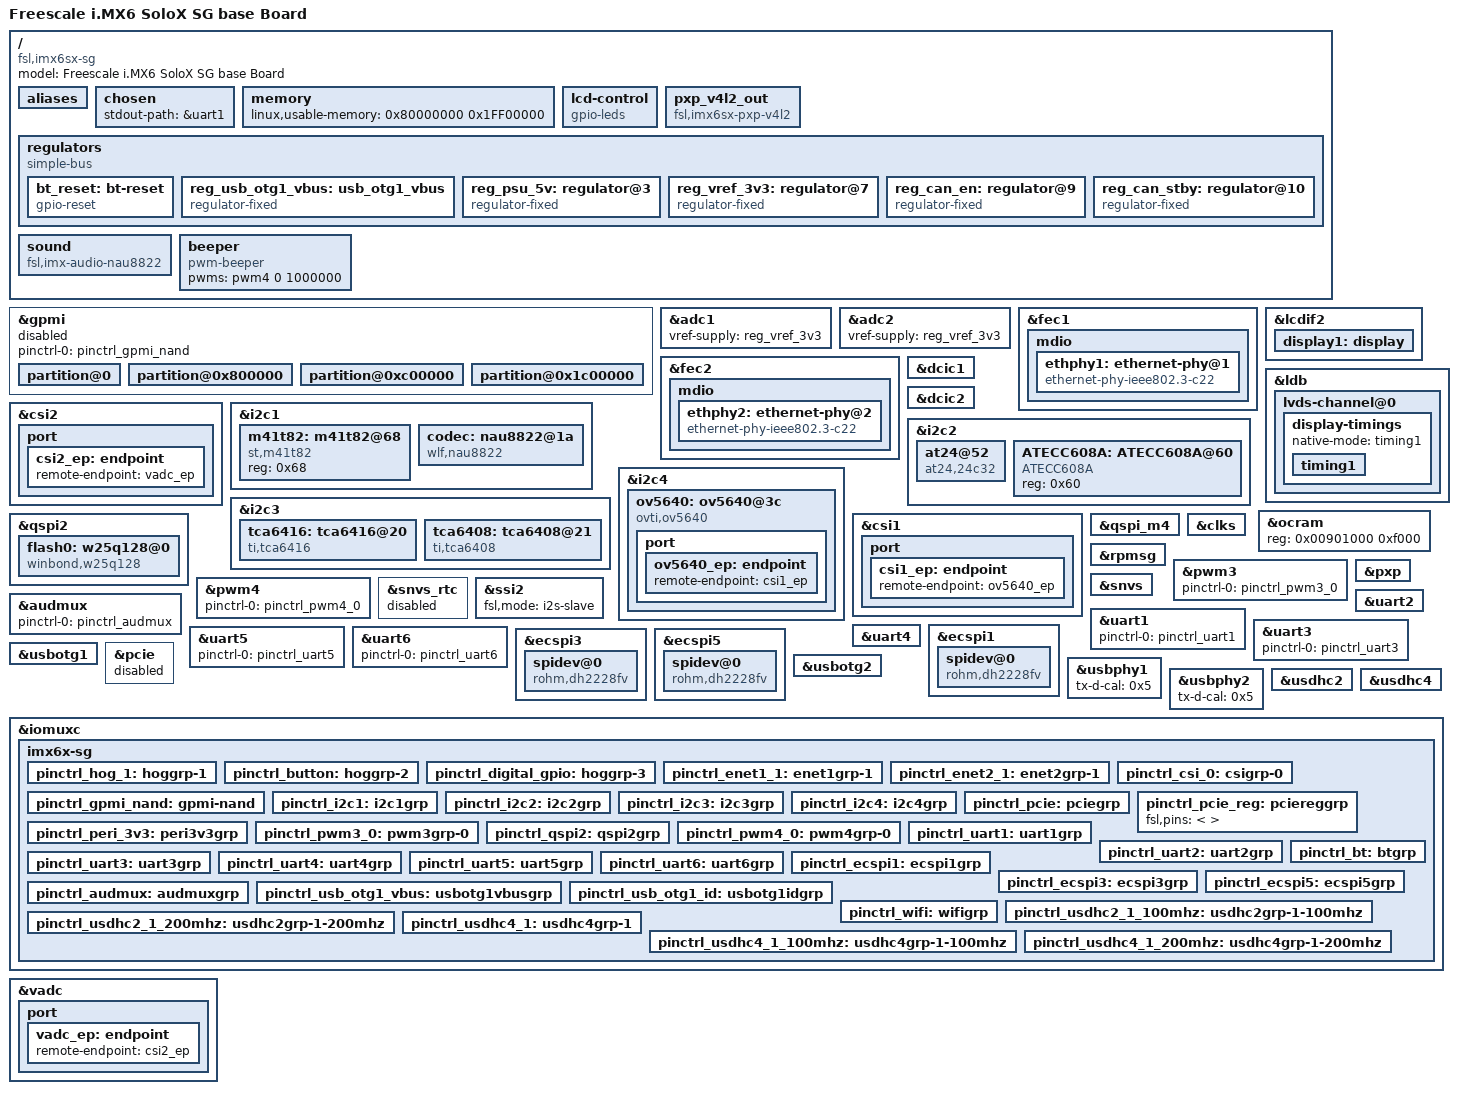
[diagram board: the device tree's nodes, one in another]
/*
 * Copyright (C) 2014 Freescale Semiconductor, Inc.
 *
 * This program is free software; you can redistribute it and/or modify
 * it under the terms of the GNU General Public License version 2 as
 * published by the Free Software Foundation.
 */

/dts-v1/;

#include <dt-bindings/gpio/gpio.h>
#include <dt-bindings/input/input.h>
#include "imx6sx.dtsi"

/ {
	model = "Freescale i.MX6 SoloX SG base Board";
	compatible = "fsl,imx6sx-sg", "fsl,imx6sx";
	
	aliases {
        
    };
	
	chosen {
		stdout-path = &uart1;
		//stdout-path = &mxcfb1;
	};

	memory {
		linux,usable-memory = <0x80000000 0x1FF00000>;
	};
	
	lcd-control {
		compatible = "gpio-leds";
	};

	pxp_v4l2_out {
		compatible = "fsl,imx6sx-pxp-v4l2", "fsl,imx6sl-pxp-v4l2";
		status = "okay";
	};

	regulators {
		compatible = "simple-bus";
		#address-cells = <1>;
		#size-cells = <0>;

        bt_reset: bt-reset {
			compatible = "gpio-reset";
			reset-gpios = <&gpio1 2 GPIO_ACTIVE_LOW>;
			reset-delay-us = <1000>;
			#reset-cells = <0>;
		};

		reg_usb_otg1_vbus: usb_otg1_vbus {
			compatible = "regulator-fixed";
			reg = <1>;
			pinctrl-names = "default";
			pinctrl-0 = <&pinctrl_usb_otg1_vbus>;
			regulator-name = "usb_otg1_vbus";
			regulator-min-microvolt = <5000000>;
			regulator-max-microvolt = <5000000>;
			gpio = <&gpio4 18 GPIO_ACTIVE_HIGH>;
			enable-active-high;
		};
		
		reg_psu_5v: regulator@3 {
			compatible = "regulator-fixed";
			reg = <3>;
			regulator-name = "PSU-5V0";
			regulator-min-microvolt = <5000000>;
			regulator-max-microvolt = <5000000>;
		};

		reg_vref_3v3: regulator@7 {
			compatible = "regulator-fixed";
			reg = <7>;
			regulator-name = "vref-3v3";
			regulator-min-microvolt = <3300000>;
			regulator-max-microvolt = <3300000>;
		};

		reg_can_en: regulator@9 {
			compatible = "regulator-fixed";
			reg = <9>;
			regulator-name = "can-en";
			regulator-min-microvolt = <3300000>;
			regulator-max-microvolt = <3300000>;
		};

		reg_can_stby: regulator@10 {
			compatible = "regulator-fixed";
			reg = <10>;
			regulator-name = "can-stby";
			regulator-min-microvolt = <3300000>;
			regulator-max-microvolt = <3300000>;
		};
	};

	sound {
		compatible = "fsl,imx-audio-nau8822";
		model = "nau8822-audio";
		ssi-controller = <&ssi2>;
		audio-codec = <&codec>;
		audio-routing =
			"Mic Bias", "AMIC";
		mux-int-port = <2>;
		mux-ext-port = <3>;
	};
	beeper {
        compatible = "pwm-beeper";
        pwms = <&pwm4 0 1000000>;
        status = "okay";
    };
};

&gpmi {
	pinctrl-names = "default";
	pinctrl-0 = <&pinctrl_gpmi_nand>;
	status = "disabled"; 
	partition@0 {
	label = "uboot";
	reg = <0 0x800000>;
	};
	partition@0x800000 {
		label = "env";
		reg = <0x800000 0x400000>;
	};
	partition@0xc00000 {
	label = "system";
	reg = <0xc00000 0x2000000>;
	};
	partition@0x1c00000 {
	label = "rootfs";
	reg = <0x2c00000 0x3d400000>;
	};
};

&adc1 {
	vref-supply = <&reg_vref_3v3>;
	status = "okay";
};

&adc2 {
	vref-supply = <&reg_vref_3v3>;
	status = "okay";
};

&fec1 {
	pinctrl-names = "default";
	pinctrl-0 = <&pinctrl_enet1_1>;
	phy-mode = "rgmii";
	phy-handle = <&ethphy1>;
	phy-reset-gpios = <&gpio2 4 1>; 
	phy-reset-duration =<20>;
   	local-mac-address = [00 04 9F 01 1B 58];
	status = "okay";
	
	mdio {
		#address-cells = <1>;
		#size-cells = <0>;

		ethphy1: ethernet-phy@1 {
			compatible = "ethernet-phy-ieee802.3-c22";
			reg = <1>;
			micrel,led-mode = <0>;
		};
			
	};
        
	
};

&fec2 {
	pinctrl-names = "default";
	pinctrl-0 = <&pinctrl_enet2_1>;
	phy-mode = "rgmii";
	phy-handle = <&ethphy2>;  	
	phy-reset-gpios = <&gpio2 2 1>; 
	phy-reset-duration =<20>;
   	local-mac-address = [00 04 9F 01 1B 68];
	status = "okay";
       
	mdio {
		#address-cells = <1>;
		#size-cells = <0>;

		
		ethphy2: ethernet-phy@2 {
			compatible = "ethernet-phy-ieee802.3-c22";
			reg = <2>;
			micrel,led-mode = <0>;
		};

		
	};
	
};

&lcdif2 {
	//pinctrl-names = "default";
	//pinctrl-0 = <&pinctrl_lcd>;
	display = <&display1>;
	disp-dev = "ldb";
	status = "okay";
	display1: display {
		bits-per-pixel = <32>;
		bus-width = <24>;
	};
};
&ldb {
    status = "okay";
	lvds-channel@0 {
		fsl,data-mapping = "spwg";//"jeida";
		fsl,data-width = <24>;
		crtc = "lcdif2";
		status = "okay";
		display-timings {
			native-mode = <&timing1>;
			timing1: timing1 {
				clock-frequency = <51200000>;
				hactive = <1024>;
				vactive = <600>;
				hback-porch = <100>;
				hfront-porch = <100>;
				hsync-len = <120>;
				vback-porch = <10>;
				vfront-porch = <10>;
				vsync-len = <15>;
				//de-active = <1>;
			};
		};
	};
};

&csi2 {
	status = "okay";
	port {
		csi2_ep: endpoint {
			remote-endpoint = <&vadc_ep>;
		};
	};
};

&dcic1 {
	dcic_id = <0>;
	dcic_mux = "dcic-lcdif1";
	status = "okay";
};

&dcic2 {
	dcic_id = <1>;
	dcic_mux = "dcic-lvds";
	status = "okay";
};

&i2c1 {
	clock-frequency = <100000>;
        pinctrl-names = "default";
        pinctrl-0 = <&pinctrl_i2c1>;
        status = "okay";
	m41t82: m41t82@68 {
		compatible = "st,m41t82";
		reg = <0x68>;
            	status = "okay"; 
	};

	codec: nau8822@1a {
		compatible = "wlf,nau8822";
		reg = <0x1a>;
		clocks = <&clks IMX6SX_CLK_AUDIO>;
	};
};

&i2c2 {
	clock-frequency = <100000>;
        pinctrl-names = "default";
        pinctrl-0 = <&pinctrl_i2c2>;
	status = "okay";

	at24@52 {
		compatible = "at24,24c32";
		pagesize = <32>;
		reg = <0x52>;
	};
	
	ATECC608A: ATECC608A@60 {
		compatible = "ATECC608A";
		reg = <0x60>;
	};	
};

&i2c3 {
	clock-frequency = <100000>;
	pinctrl-names = "default";
	pinctrl-0 = <&pinctrl_i2c3>;
	status = "okay";
	
	tca6416: tca6416@20 {
		compatible = "ti,tca6416";
		reg = <0x20>;
		#gpio-cells = <2>;
		gpio-controller;
	};
	
	tca6408: tca6408@21 {
		compatible = "ti,tca6408";
		reg = <0x21>;
		#gpio-cells = <2>;
		gpio-controller;
	};
};

&i2c4 {
    status = "okay";
    clock-frequency = <100000>;
    pinctrl-names = "default";
    pinctrl-0 = <&pinctrl_i2c4>;

	ov5640: ov5640@3c {
		compatible = "ovti,ov5640";
		reg = <0x3c>;
		pinctrl-names = "default";
		pinctrl-0 = <&pinctrl_csi_0>;
		clocks = <&clks IMX6SX_CLK_CSI>;
		clock-names = "csi_mclk";
		cam18v-en-gpios = <&tca6416 14 0>;
		cam28v-en-gpios = <&tca6416 15 0>;
		pwn-gpios = <&gpio3 18 1>;
		rst-gpios = <&gpio3 17 0>;
		csi_id = <0>;
		mclk = <24000000>;
		mclk_source = <0>;
		port {
			ov5640_ep: endpoint {
				remote-endpoint = <&csi1_ep>;
			};
		};
	};
};

&csi1 {
    status = "okay";

    port {
        csi1_ep: endpoint {
            remote-endpoint = <&ov5640_ep>;
        };
    };
};

&ocram {
	reg = <0x00901000 0xf000>;
};

&qspi2 {
	pinctrl-names = "default";
	pinctrl-0 = <&pinctrl_qspi2>;
	status = "okay";
	ddrsmp=<0>;	//or 2

	flash0: w25q128@0 {
		#address-cells = <1>;
		#size-cells = <1>;
		compatible = "winbond,w25q128";
		spi-max-frequency = <15625000>;
		reg = <0>;
	};
};

&qspi_m4 {
	status = "okay";
};

&rpmsg{
	status = "okay";
};

&clks {
	fsl,shared-clks-number = <0x23>;//<0x1A>;
	fsl,shared-clks-index = <IMX6SX_CLK_PLL2_BUS IMX6SX_CLK_PLL2_PFD0
			IMX6SX_CLK_PLL2_PFD2 IMX6SX_CLK_PLL3_USB_OTG
			IMX6SX_CLK_PLL3_PFD1 IMX6SX_CLK_PLL3_PFD2
			IMX6SX_CLK_PLL3_PFD3 IMX6SX_CLK_PLL4_AUDIO
			IMX6SX_CLK_PLL5_VIDEO
			IMX6SX_CLK_OCRAM IMX6SX_CLK_CAN1_SERIAL
			IMX6SX_CLK_CAN1_IPG IMX6SX_CLK_CAN2_SERIAL
			IMX6SX_CLK_CAN2_IPG IMX6SX_CLK_CANFD
			IMX6SX_CLK_ECSPI1 IMX6SX_CLK_ECSPI2
			IMX6SX_CLK_ECSPI3 IMX6SX_CLK_ECSPI4
			IMX6SX_CLK_ECSPI5 IMX6SX_CLK_QSPI1
			IMX6SX_CLK_QSPI2 IMX6SX_CLK_SSI1
			IMX6SX_CLK_SSI2 IMX6SX_CLK_SSI3
			IMX6SX_CLK_UART_SERIAL IMX6SX_CLK_UART_IPG
			IMX6SX_CLK_PERIPH_CLK2_SEL IMX6SX_CLK_DUMMY
			IMX6SX_CLK_I2C1 IMX6SX_CLK_I2C2
			IMX6SX_CLK_I2C3 IMX6SX_CLK_I2C4
			IMX6SX_CLK_EPIT1 IMX6SX_CLK_EPIT2>;
	fsl,shared-mem-addr = <0x91F000>;
	fsl,shared-mem-size = <0x1000>;
};

&pwm3 {
	pinctrl-names = "default";
	pinctrl-0 = <&pinctrl_pwm3_0>;
	status = "okay";
};

&pwm4 {
	pinctrl-names = "default";
	pinctrl-0 = <&pinctrl_pwm4_0>;
	status = "okay";
};


&pxp {
    status = "okay";
};

&snvs{
	status = "okay";
};

&snvs_rtc {
    status = "disabled";
};

&ssi2 {
	fsl,mode = "i2s-slave";
	status = "okay";
};

&audmux {  
    pinctrl-names = "default";  
    pinctrl-0 = <&pinctrl_audmux>;  
    status = "okay";  
};

//debug serial
&uart1 {
	pinctrl-names = "default";
	pinctrl-0 = <&pinctrl_uart1>;
	status = "okay";
};

//BM28: BT
&uart2 {
	pinctrl-names = "default";
	    pinctrl-0 = <&pinctrl_uart2
                        &pinctrl_bt>;
    fsl,uart-has-rtscts;
    resets = <&bt_reset>;
	status = "okay";
};

//Port P3: LTE EXPANSION
&uart3 {
	pinctrl-names = "default";
	pinctrl-0 = <&pinctrl_uart3>;
	status = "okay";
};

//Common port2 and module 485
&uart4 {
    pinctrl-names = "default";
    pinctrl-0 = <&pinctrl_uart4>;
	fsl,uart-has-rtscts;
    status = "okay";
};

//Common port1 and module 485
&uart5 {
	pinctrl-names = "default";
	pinctrl-0 = <&pinctrl_uart5>;
	status = "okay";
};

//rs232/ttl232
&uart6 {
	pinctrl-names = "default";
	pinctrl-0 = <&pinctrl_uart6>;
	//fsl,uart-has-rtscts;
	status = "okay";
};

//PORT P1: Common module
&ecspi1 {
	fsl,spi-num-chipselects = <1>;
	cs-gpios = <&gpio4 22 GPIO_ACTIVE_LOW>;
	pinctrl-names = "default";
	pinctrl-0 = <&pinctrl_ecspi1>;
	status = "okay";
	spidev@0 {
		compatible = "rohm,dh2228fv";
		spi-max-frequency = <20000000>;
		reg = <0>;
		dmas = <&sdma 3 7 1>, <&sdma 4 7 2>;
		dma-names = "rx", "tx";
	};
};

//Port P2: Common module
&ecspi3 {
    fsl,spi-num-chipselects = <1>;
    cs-gpios = <&gpio4 30 GPIO_ACTIVE_LOW>;
    
    pinctrl-names = "default";
    pinctrl-0 = <&pinctrl_ecspi3>;
    status = "okay";
    spidev@0 {
            compatible = "rohm,dh2228fv";
            spi-max-frequency = <20000000>;
            reg = <0>;
            dmas = <&sdma 7 7 1>, <&sdma 8 7 2>;
            dma-names = "rx", "tx";
        };
};

//Port P3: LTE EXPANSION
&ecspi5 {
	fsl,spi-num-chipselects = <1>;
	cs-gpios = <&gpio4 28 GPIO_ACTIVE_LOW>;
	pinctrl-names = "default";
	pinctrl-0 = <&pinctrl_ecspi5>;
	status = "okay";
	spidev@0 {
		compatible = "rohm,dh2228fv";
		spi-max-frequency = <20000000>;
		reg = <0>;
		dmas = <&sdma 11 7 1>, <&sdma 12 7 2>;
		dma-names = "rx", "tx";
	};
};

&usbotg1 {
	vbus-supply = <&reg_usb_otg1_vbus>;
	pinctrl-names = "default";
	pinctrl-0 = <&pinctrl_usb_otg1_id>;
	//disable-over-current;
	srp-disable;
	hnp-disable;
	adp-disable;
    dr_mode = "otg";
	status = "okay";
};

//Port P3: LTE EXPANSION
&usbotg2 {
        pinctrl-names = "default";
        srp-disable;
        hnp-disable;
        adp-disable;
        dr_mode = "host";
        status = "okay";
};

&usbphy1 {
        tx-d-cal = <0x5>;
};

&usbphy2 {
        tx-d-cal = <0x5>;
};

//BM28: Wifi
&usdhc2 {
	pinctrl-names = "default", "state_100mhz", "state_200mhz";
	pinctrl-0 = <&pinctrl_wifi>;
        pinctrl-1 = <&pinctrl_usdhc2_1_100mhz>;
        pinctrl-2 = <&pinctrl_usdhc2_1_200mhz>;
	non-removable;
	wifi-host;
	keep-power-in-suspend;
	enable-sdio-wakeup;
	status = "okay";
};

&usdhc4 {
	pinctrl-names = "default";
	pinctrl-0 = <&pinctrl_usdhc4_1>;
	bus-width = <8>;
	non-removable;
	no-1-8-v;
	keep-power-in-suspend;
	enable-sdio-wakeup;
	status = "okay";
};

&pcie {
	pinctrl-names = "default";
	pinctrl-0 = <&pinctrl_pcie>;
	reset-gpio = <&gpio3 4 0>;
	disable-gpio = <&gpio4 4 0>;
	status = "disabled";
};

&iomuxc {
	pinctrl-names = "default";
	pinctrl-0 = <
        &pinctrl_hog_1
        &pinctrl_button
        &pinctrl_digital_gpio
    >;
	imx6x-sg {
		pinctrl_hog_1: hoggrp-1 {
			fsl,pins = <
				MX6SX_PAD_USB_H_DATA__GPIO7_IO_10	0x83030
			>;
		};
		
        pinctrl_button: hoggrp-2 {
            fsl,pins = <
                /* button pull up */
                MX6SX_PAD_GPIO1_IO11__GPIO1_IO_11        0xF000
                MX6SX_PAD_NAND_RE_B__GPIO4_IO_12         0xF000
            >;
        };

        pinctrl_digital_gpio: hoggrp-3 {
            fsl,pins = <
				MX6SX_PAD_LCD1_DATA00__GPIO3_IO_1        0x110b0
				MX6SX_PAD_LCD1_DATA01__GPIO3_IO_2        0x110b0
                MX6SX_PAD_LCD1_DATA02__GPIO3_IO_3        0x110b0
                MX6SX_PAD_LCD1_DATA23__GPIO3_IO_24       0x110b0
           >;
        };

		pinctrl_enet1_1: enet1grp-1 {
			fsl,pins = <
				MX6SX_PAD_ENET2_COL__ENET1_MDC        	0xa0b1 
				MX6SX_PAD_ENET2_CRS__ENET1_MDIO        	0xa0b1 
				MX6SX_PAD_RGMII1_TXC__ENET1_RGMII_TXC   0xa0b9
				MX6SX_PAD_RGMII1_TD0__ENET1_TX_DATA_0   0xa0b1
				MX6SX_PAD_RGMII1_TD1__ENET1_TX_DATA_1   0xa0b1
				MX6SX_PAD_RGMII1_TD2__ENET1_TX_DATA_2	0xa0b1
				MX6SX_PAD_RGMII1_TD3__ENET1_TX_DATA_3	0xa0b1
				MX6SX_PAD_RGMII1_TX_CTL__ENET1_TX_EN	0xa0b1
				MX6SX_PAD_RGMII1_RXC__ENET1_RX_CLK 	0x3081
				MX6SX_PAD_RGMII1_RD0__ENET1_RX_DATA_0   0x3081
				MX6SX_PAD_RGMII1_RD1__ENET1_RX_DATA_1   0x3081
				MX6SX_PAD_RGMII1_RD2__ENET1_RX_DATA_2	0x3081
				MX6SX_PAD_RGMII1_RD3__ENET1_RX_DATA_3	0x3081
				MX6SX_PAD_RGMII1_RX_CTL__ENET1_RX_EN   	0x3081
				MX6SX_PAD_ENET1_RX_CLK__GPIO2_IO_4 	0xb099
				//MX6SX_PAD_ENET1_TX_CLK__ENET1_REF_CLK1  0x4000b099 
				MX6SX_PAD_ENET1_TX_CLK__GPIO2_IO_5	0xb099
				
			>;
		};

		
		pinctrl_enet2_1: enet2grp-1{
			fsl,pins = <
				MX6SX_PAD_ENET1_COL__ENET2_MDC          0xa0b1 
				MX6SX_PAD_ENET1_CRS__ENET2_MDIO         0xa0b1
				MX6SX_PAD_RGMII2_RX_CTL__ENET2_RX_EN    0xb099
				MX6SX_PAD_RGMII2_RD0__ENET2_RX_DATA_0   0x3081
				MX6SX_PAD_RGMII2_RD1__ENET2_RX_DATA_1   0x3081
				MX6SX_PAD_RGMII2_RD2__ENET2_RX_DATA_2	0x3081
				MX6SX_PAD_RGMII1_RD3__ENET1_RX_DATA_3	0x3081
                MX6SX_PAD_RGMII2_RXC__ENET2_RX_ER       0xb099
				MX6SX_PAD_RGMII2_TX_CTL__ENET2_TX_EN    0xb099
				MX6SX_PAD_RGMII2_TXC__ENET2_RGMII_TXC
				MX6SX_PAD_RGMII2_TD0__ENET2_TX_DATA_0   0xa0b1 
				MX6SX_PAD_RGMII2_TD1__ENET2_TX_DATA_1   0xa0b1
				MX6SX_PAD_RGMII2_TD2__ENET2_TX_DATA_2	0xa0b1
				MX6SX_PAD_RGMII2_TD3__ENET2_TX_DATA_3	0xa0b1
				MX6SX_PAD_ENET1_MDC__GPIO2_IO_2       0xb099   
				//MX6SX_PAD_ENET2_TX_CLK__ENET2_REF_CLK2	0x4000b099
				MX6SX_PAD_ENET2_TX_CLK__GPIO2_IO_9	0xb099
                >;
		};

        pinctrl_csi_0: csigrp-0 {
            fsl,pins = <
                MX6SX_PAD_LCD1_DATA07__CSI1_MCLK        0x110b0
                MX6SX_PAD_LCD1_DATA06__CSI1_PIXCLK      0x110b0
                MX6SX_PAD_LCD1_DATA04__CSI1_VSYNC       0x110b0
                MX6SX_PAD_LCD1_DATA05__CSI1_HSYNC       0x110b0
                MX6SX_PAD_LCD1_DATA15__CSI1_DATA_2      0x110b0
                MX6SX_PAD_LCD1_DATA14__CSI1_DATA_3      0x110b0
                MX6SX_PAD_LCD1_DATA13__CSI1_DATA_4      0x110b0
                MX6SX_PAD_LCD1_DATA12__CSI1_DATA_5      0x110b0
                MX6SX_PAD_LCD1_DATA11__CSI1_DATA_6      0x110b0
                MX6SX_PAD_LCD1_DATA10__CSI1_DATA_7      0x110b0
                MX6SX_PAD_LCD1_DATA09__CSI1_DATA_8      0x110b0
                MX6SX_PAD_LCD1_DATA08__CSI1_DATA_9      0x110b0
                MX6SX_PAD_LCD1_DATA16__GPIO3_IO_17         0x80000000
                MX6SX_PAD_LCD1_DATA17__GPIO3_IO_18         0x80000000
              >;
       };

		pinctrl_gpmi_nand: gpmi-nand {
			fsl,pins = <
				MX6SX_PAD_NAND_CLE__RAWNAND_CLE         0xb0b1
				MX6SX_PAD_NAND_ALE__RAWNAND_ALE         0xb091
				MX6SX_PAD_NAND_WP_B__RAWNAND_WP_B       0xb0b1
				MX6SX_PAD_NAND_READY_B__RAWNAND_READY_B 0xb000
				MX6SX_PAD_NAND_CE0_B__RAWNAND_CE0_B     0xb0b1
				MX6SX_PAD_NAND_RE_B__RAWNAND_RE_B       0xb091
				MX6SX_PAD_NAND_WE_B__RAWNAND_WE_B       0xb091
				MX6SX_PAD_NAND_DATA00__RAWNAND_DATA00   0xb091
				MX6SX_PAD_NAND_DATA01__RAWNAND_DATA01   0xb091
				MX6SX_PAD_NAND_DATA02__RAWNAND_DATA02   0xb091
				MX6SX_PAD_NAND_DATA03__RAWNAND_DATA03   0xb091
				MX6SX_PAD_NAND_DATA04__RAWNAND_DATA04   0xb091
				MX6SX_PAD_NAND_DATA05__RAWNAND_DATA05   0xb091
				MX6SX_PAD_NAND_DATA06__RAWNAND_DATA06   0xb091
				MX6SX_PAD_NAND_DATA07__RAWNAND_DATA07   0xb091
			>;
		};

		pinctrl_i2c1: i2c1grp {
			fsl,pins = <
				MX6SX_PAD_GPIO1_IO01__I2C1_SDA		0x4001b8b1
				MX6SX_PAD_GPIO1_IO00__I2C1_SCL		0x4001b8b1
			>;
		};

		pinctrl_i2c2: i2c2grp {
			fsl,pins = <
				MX6SX_PAD_QSPI1B_DATA2__I2C2_SDA 0x4001b8b1                          
				MX6SX_PAD_QSPI1B_DATA3__I2C2_SCL  0x4001b8b1
			>;
		};

		pinctrl_i2c3: i2c3grp {
			fsl,pins = <
				MX6SX_PAD_KEY_ROW4__I2C3_SDA 0x4001b8b1
				MX6SX_PAD_KEY_COL4__I2C3_SCL 0x4001b8b1
			>;
		};
		
		pinctrl_i2c4: i2c4grp {
            fsl,pins = <
                MX6SX_PAD_SD3_DATA0__I2C4_SCL      0x4001b8b1
                MX6SX_PAD_SD3_DATA1__I2C4_SDA      0x4001b8b1
            >;
        };

		pinctrl_pcie: pciegrp {
			fsl,pins = <
                MX6SX_PAD_NAND_DATA00__GPIO4_IO_4        0x10b0
                MX6SX_PAD_LCD1_DATA03__GPIO3_IO_4      0x10b0
			>;
		};

		pinctrl_pcie_reg: pciereggrp {
			fsl,pins = <
                //MX6SX_PAD_LCD1_DATA00__GPIO3_IO_1       0x10b
			>;
		};

		pinctrl_peri_3v3: peri3v3grp {
			fsl,pins = <
				MX6SX_PAD_QSPI1A_DATA0__GPIO4_IO_16	0x80000000
			>;
		};

		pinctrl_pwm3_0: pwm3grp-0 {
			fsl,pins = <
				MX6SX_PAD_GPIO1_IO12__PWM3_OUT 0x1b0b1	//old: 0x110b0
			>;
		};	
		
		pinctrl_qspi2: qspi2grp {
			fsl,pins = <
				MX6SX_PAD_NAND_CLE__QSPI2_A_SCLK		0x70a1
				MX6SX_PAD_NAND_CE1_B__QSPI2_A_DATA_3	0x70a1
				MX6SX_PAD_NAND_CE0_B__QSPI2_A_DATA_2	0x70a1
				MX6SX_PAD_NAND_READY_B__QSPI2_A_DATA_1	0x70a1
				MX6SX_PAD_NAND_WP_B__QSPI2_A_DATA_0		0x70a1
				MX6SX_PAD_NAND_ALE__QSPI2_A_SS0_B		0x70a1
			>;
		};

		pinctrl_pwm4_0: pwm4grp-0 {
			fsl,pins = <
				MX6SX_PAD_GPIO1_IO13__PWM4_OUT 0x1b0b1	//old: 0x110b0
			>;
		};

		/* uart1 is used by A9 console*/
		pinctrl_uart1: uart1grp {
			fsl,pins = <
				MX6SX_PAD_GPIO1_IO04__UART1_TX		0x1b0b1
				MX6SX_PAD_GPIO1_IO05__UART1_RX		0x1b0b1
			>;
		};

        /*BM28*/
		pinctrl_uart2: uart2grp {
			fsl,pins = <
				MX6SX_PAD_GPIO1_IO06__UART2_TX		0x1b0b1
				MX6SX_PAD_GPIO1_IO07__UART2_RX		0x1b0b1
                MX6SX_PAD_GPIO1_IO08__UART2_RTS_B   0x1b0b1
                MX6SX_PAD_GPIO1_IO09__UART2_CTS_B   0x1b0b1
			>;
		};
		/*Cellular module*/
		pinctrl_uart3: uart3grp {
			fsl,pins = <
				MX6SX_PAD_SD3_DATA5__UART3_TX		0x1b0b1
				MX6SX_PAD_SD3_DATA4__UART3_RX		0x1b0b1
				MX6SX_PAD_SD3_DATA6__UART3_RTS_B	0x1b0b1
				MX6SX_PAD_SD3_DATA7__UART3_CTS_B	0x1b0b1
			>;
		};

        pinctrl_bt: btgrp {
            fsl,pins = <
                MX6SX_PAD_GPIO1_IO02__GPIO1_IO_2    0x13069 /* BT_REG_ON */
            >;
        };

		/*Used by common port2 and module 485*/
		pinctrl_uart4: uart4grp {
			fsl,pins = <
				MX6SX_PAD_SD3_CMD__UART4_TX		0x1b0b1
				MX6SX_PAD_SD3_DATA3__UART4_RX		0x1b0b1
				//MX6SX_PAD_SD3_CLK__UART4_CTS_B          0x1b0b1
				//MX6SX_PAD_SD3_DATA2__UART4_RTS_B        0x1b0b1
			>;
		};
		
		/*Used by Common port1 and module 485*/
		pinctrl_uart5: uart5grp {
			fsl,pins = <
				MX6SX_PAD_KEY_COL3__UART5_TX		0x1b0b1
				MX6SX_PAD_KEY_ROW3__UART5_RX		0x1b0b1
			>;
		};
		
		/*uart6 is for rs232/ttl232*/
		pinctrl_uart6: uart6grp {
			fsl,pins = <
				MX6SX_PAD_KEY_COL1__UART6_TX 0x1b0b1
				MX6SX_PAD_KEY_ROW1__UART6_RX 0x1b0b1
				//MX6SX_PAD_CSI_DATA06__UART6_RTS_B       0x1b0b1
				//MX6SX_PAD_CSI_DATA07__UART6_CTS_B       0x1b0b1
			>;
		};
		
		pinctrl_ecspi1: ecspi1grp {
			fsl,pins = <
				MX6SX_PAD_QSPI1A_DATA0__ECSPI1_MOSI 0x1b091
				MX6SX_PAD_QSPI1A_DATA1__ECSPI1_MISO 0x1b091
				MX6SX_PAD_QSPI1A_SCLK__ECSPI1_SCLK  0x1b099
				MX6SX_PAD_QSPI1A_SS0_B__GPIO4_IO_22 0x0b0b9
			>;
		};
		
        pinctrl_ecspi3: ecspi3grp {
            fsl,pins = <
                MX6SX_PAD_QSPI1B_DATA0__ECSPI3_MOSI 0x1b091
                MX6SX_PAD_QSPI1B_DATA1__ECSPI3_MISO 0x1b091
                MX6SX_PAD_QSPI1B_SCLK__ECSPI3_SCLK  0x1b099
                MX6SX_PAD_QSPI1B_SS0_B__GPIO4_IO_30 0x0b0b9
            >;
        };
                        
		//Port P3: LTE EXPANSION
		pinctrl_ecspi5: ecspi5grp {
			fsl,pins = <
				MX6SX_PAD_QSPI1A_DQS__ECSPI5_MOSI   0x1b091
				MX6SX_PAD_QSPI1A_SS1_B__ECSPI5_MISO 0x1b091
				MX6SX_PAD_QSPI1B_SS1_B__ECSPI5_SCLK 0x1b099
				MX6SX_PAD_QSPI1B_DQS__GPIO4_IO_28   0x0b0b9
			>;
		};
		
		pinctrl_audmux: audmuxgrp {
			fsl,pins = <
				MX6SX_PAD_LCD1_RESET__AUDMUX_AUD3_RXD    0x130b0
				MX6SX_PAD_LCD1_ENABLE__AUDMUX_AUD3_TXC   0x130b0
				MX6SX_PAD_LCD1_HSYNC__AUDMUX_AUD3_TXD    0x12098
				MX6SX_PAD_LCD1_VSYNC__AUDMUX_AUD3_TXFS   0x130b0
				MX6SX_PAD_ENET1_MDIO__AUDMUX_MCLK        0x13098
			>;
		};		

		pinctrl_usb_otg1_vbus: usbotg1vbusgrp {
			fsl,pins = <
				MX6SX_PAD_QSPI1A_DATA2__GPIO4_IO_18     0x10b0
			>;
		};

		pinctrl_usb_otg1_id: usbotg1idgrp {
			fsl,pins = <
				MX6SX_PAD_GPIO1_IO10__ANATOP_OTG1_ID 	0x17059
				MX6SX_PAD_QSPI1A_DATA3__USB_OTG1_OC	0x17059
			>;
		};

		pinctrl_wifi: wifigrp {
			fsl,pins = <
				MX6SX_PAD_SD2_CMD__USDHC2_CMD		0x17059
				MX6SX_PAD_SD2_CLK__USDHC2_CLK		0x170f9
				MX6SX_PAD_SD2_DATA0__USDHC2_DATA0	0x17059
				MX6SX_PAD_SD2_DATA1__USDHC2_DATA1	0x17059
				MX6SX_PAD_SD2_DATA2__USDHC2_DATA2	0x17059
				MX6SX_PAD_SD2_DATA3__USDHC2_DATA3	0x17059
                MX6SX_PAD_KEY_COL0__GPIO2_IO_10  	0x17059	/* REG_ON UART6_RTS_B*/
			>;
		};

		pinctrl_usdhc2_1_100mhz: usdhc2grp-1-100mhz {
                        fsl,pins = <
                                MX6SX_PAD_SD2_CMD__USDHC2_CMD           0x170b9
                                MX6SX_PAD_SD2_CLK__USDHC2_CLK           0x100b9
                                MX6SX_PAD_SD2_DATA0__USDHC2_DATA0       0x170b9
                                MX6SX_PAD_SD2_DATA1__USDHC2_DATA1       0x170b9
                                MX6SX_PAD_SD2_DATA2__USDHC2_DATA2       0x170b9
                                MX6SX_PAD_SD2_DATA3__USDHC2_DATA3       0x170b9
                        >;
                };

                pinctrl_usdhc2_1_200mhz: usdhc2grp-1-200mhz {
                        fsl,pins = <
                                MX6SX_PAD_SD2_CMD__USDHC2_CMD           0x170f9
                                MX6SX_PAD_SD2_CLK__USDHC2_CLK           0x100f9
                                MX6SX_PAD_SD2_DATA0__USDHC2_DATA0       0x170f9
                                MX6SX_PAD_SD2_DATA1__USDHC2_DATA1       0x170f9
                                MX6SX_PAD_SD2_DATA2__USDHC2_DATA2       0x170f9
                                MX6SX_PAD_SD2_DATA3__USDHC2_DATA3       0x170f9
                        >;
                };
		
		pinctrl_usdhc4_1: usdhc4grp-1 {
			fsl,pins = <
				MX6SX_PAD_SD4_CMD__USDHC4_CMD		0x170D1
				MX6SX_PAD_SD4_CLK__USDHC4_CLK		0x100f9
				MX6SX_PAD_SD4_DATA0__USDHC4_DATA0	0x170D1
				MX6SX_PAD_SD4_DATA1__USDHC4_DATA1	0x170D1
				MX6SX_PAD_SD4_DATA2__USDHC4_DATA2	0x170D1
				MX6SX_PAD_SD4_DATA3__USDHC4_DATA3	0x170D1
				MX6SX_PAD_SD4_DATA4__USDHC4_DATA4	0x170D1
				MX6SX_PAD_SD4_DATA5__USDHC4_DATA5	0x170D1
				MX6SX_PAD_SD4_DATA6__USDHC4_DATA6	0x170D1
				MX6SX_PAD_SD4_DATA7__USDHC4_DATA7	0x170D1
				MX6SX_PAD_SD4_RESET_B__USDHC4_RESET_B	0x170D1
			>;
		};

		pinctrl_usdhc4_1_100mhz: usdhc4grp-1-100mhz {
			fsl,pins = <
				MX6SX_PAD_SD4_CMD__USDHC4_CMD		0x170b9
				MX6SX_PAD_SD4_CLK__USDHC4_CLK		0x100b9
				MX6SX_PAD_SD4_DATA0__USDHC4_DATA0	0x170b9
				MX6SX_PAD_SD4_DATA1__USDHC4_DATA1	0x170b9
				MX6SX_PAD_SD4_DATA2__USDHC4_DATA2	0x170b9
				MX6SX_PAD_SD4_DATA3__USDHC4_DATA3	0x170b9
				MX6SX_PAD_SD4_DATA4__USDHC4_DATA4	0x170b9
				MX6SX_PAD_SD4_DATA5__USDHC4_DATA5	0x170b9
				MX6SX_PAD_SD4_DATA6__USDHC4_DATA6	0x170b9
				MX6SX_PAD_SD4_DATA7__USDHC4_DATA7	0x170b9
			>;
		};

		pinctrl_usdhc4_1_200mhz: usdhc4grp-1-200mhz {
			fsl,pins = <
				MX6SX_PAD_SD4_CMD__USDHC4_CMD		0x170f9
				MX6SX_PAD_SD4_CLK__USDHC4_CLK		0x100f9
				MX6SX_PAD_SD4_DATA0__USDHC4_DATA0	0x170f9
				MX6SX_PAD_SD4_DATA1__USDHC4_DATA1	0x170f9
				MX6SX_PAD_SD4_DATA2__USDHC4_DATA2	0x170f9
				MX6SX_PAD_SD4_DATA3__USDHC4_DATA3	0x170f9
				MX6SX_PAD_SD4_DATA4__USDHC4_DATA4	0x170f9
				MX6SX_PAD_SD4_DATA5__USDHC4_DATA5	0x170f9
				MX6SX_PAD_SD4_DATA6__USDHC4_DATA6	0x170f9
				MX6SX_PAD_SD4_DATA7__USDHC4_DATA7	0x170f9
			>;
		};
		
	};
};

&vadc {
	vadc_in = <0>;
	csi_id = <1>;
	status = "okay";
	port {
		vadc_ep: endpoint {
			remote-endpoint = <&csi2_ep>;
		};
	};
};
